# TLE986x register map
File version: 2.5
Registers are 32-bit, read-write, reset 0x0 unless marked. A register's access mark holds for its fields unless they carry their own. Offsets are from the block's base; [hi:lo] are bit positions.

## DMA
Base 0x50014000
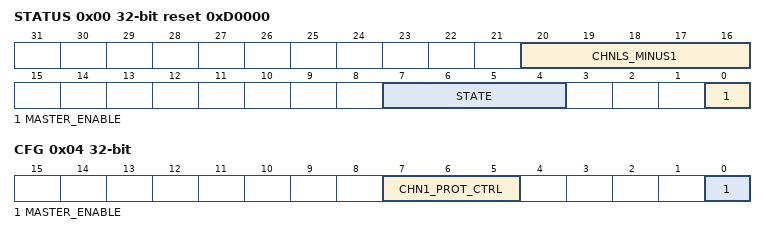
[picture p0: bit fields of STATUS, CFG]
0x00 STATUS ro reset 0xD0000 — DMA Status
  [20:16] CHNLS_MINUS1 — Available Channels minus 1
    13=controller configured to use 14 DMA channels
  [7:4] STATE — Current State of the Control State Machine
    0=idle; 1=reading channel controller date; 2=reading source data end pointer; 3=reading destination data end pointer; 4=reading source data; 5=writing destination data; 6=waiting for DMA request to clear; 7=writing channel controller data; 8=stalled; 9=done; 10=peripheral scatter-gather transition
  [0] MASTER_ENABLE — Enable Status of the Controller
    0=DISABLED (controller is disabled); 1=ENABLED (controller is enabled)
0x04 CFG wo — DMA Configuration
  [7:5] CHN1_PROT_CTRL
  [0] MASTER_ENABLE — Enable for the Controller
    0=DISABLE (disables the controller); 1=ENABLE (enables the controller)
0x08 CTRL_BASE_PTR — Channel Control Data Base Pointer
  [31:9] CTRL_BASE_PTR
0x0C ALT_CTRL_BASE_PTR ro reset 0x100 — Channel Alternate Control Data Base Pointer
  [31:0] ALT_CTRL_BASE_PTR — Base Address of the Alternate Data Structure
0x10 WAITONREQ_STATUS ro — Channel Wait on Request Status
  [13:0] WAITONREQ_STATUS
    0=LOW (dma_waitonreq[C] is LOW.); 1=HIGH (dma_waitonreq[C] is HIGH.)
0x14 CHNL_SW_REQUEST wo — Channel Software Request
  [13:0] CHNL_SW_REQUEST
    0=does not create a DMA request for channel C; 1=creates a DMA request for channel C
0x18 CHNL_USEBURST_SET — Channel Useburst Set
  [13:0] CHNL_USEBURST_SET — CHNL_USEBURST_SET: 0b0=on read: DMA channel n responds to requests that it receives on dma_req[C] or dma_sreq[C]. The controller performs 2, or single, bus transfers., 0b1=on read: DMA channel n does not respond to requests that it receives on dma_req[C] or dma_sreq[C]. The controller only reponds to dma_req[C] requests and performs 2 transfers., 0b0=on write: No effect. Use the CHNL_USEBURST_CLR Register to set bit [C] to 0., 0b1=on write: Disables dma_sreq[C] from generating DMA requests. The controller performs 2 transfers.,
0x1C CHNL_USEBURST_CLR wo — Channel Useburst Clear
  [13:0] CHNL_USEBURST_CLR
    0=No effect. Use the CHNL_USEBURST_SET Register to disable dma_sreq[] from generating requests.; 1=Enables dma_sreq[C] to generate DMA requests
0x20 CHNL_REQ_MASK_SET — Channel Request Mask Set
  [13:0] CHNL_REQ_MASK_SET — CHNL_REQ_MASK_SET: 0b0=on read: External requests are enabled for channel C., 0b1=on read: External requests are disabled for channel C., 0b0=on write: No effect. Use the CHNL_REQ_MASK_CLR Register to enable DMA requests., 0b1=on write: Disables dma_req[C] and dma_sreq[C] from generating DMA requests.,
0x24 CHNL_REQ_MASK_CLR wo — Channel Request Mask Clear
  [13:0] CHNL_REQ_MASK_CLR
    0=No effect. Use the CHNL_REQ_MASK_SET Register to disable dma_req[] and dma_sreq[] from generating requests.; 1=Enables dma_req[C] or dma_sreq[C] to generate DMA request
0x28 CHNL_ENABLE_SET — Channel Enable Set
  [13:0] CHNL_ENABLE_SET — CHNL_ENABLE_SET: 0b0=on read: Channel C is disabled., 0b1=on read: Channel C is enabled., 0b0=on write: No effect. Use the CHNL_ENABLE_CLR Register to disable a channel., 0b1=on write: Enables channel C.,
0x2C CHNL_ENABLE_CLR wo — Channel Enable Clear
  [13:0] CHNL_ENABLE_CLR
    0=No effect. Use the CHNL_ENABLE_SET Register to enable DMA channels.; 1=Disables channel C
0x30 CHNL_PRI_ALT_SET — Channel Primary-Alternate Set
  [13:0] CHNL_PRI_ALT_SET — CHNL_PRI_ALT_SET: 0b0=on read: DMA channel C is using the primary data structure., 0b1=on read: DMA channel C is using the alternate data structure., 0b0=on write: No effect. Use the CHNL_PRI_ALT_CLR Register to set bit [C] to 0., 0b1=on write: Selects the alternate data structure for channel C.,
0x34 CHNL_PRI_ALT_CLR wo — Channel Primary-Alternate Clear
  [13:0] CHNL_PRI_ALT_CLR
    0=No effect. Use the CHNL_PRI_ALT_SET Register to select the alternate data structure.; 1=Selects the primary data structure for channel C
0x38 CHNL_PRIORITY_SET — Channel Priority Set
  [13:0] CHNL_PRIORITY_SET — CHNL_PRIORITY_SET: 0b0=on read: DMA channel C is using the default priority level., 0b1=on read: DMA channel C is using a high priority level., 0b0=on write: No effect. Use the CHNL_ENABLE_CLR Register to set channel C to the default priority level., 0b1=on write: Channel C uses the high priority level.,
0x3C CHNL_PRIORITY_CLR wo — Channel Priority Clear
  [13:0] CHNL_PRIORITY_CLR
    0=No effect. Use the CHNL_ENABLE_SET Register to set channel C to the high priority level.; 1=Channel C uses the default priority level
0x4C ERR_CLR — Bus Error Clear
  [0] ERR_CLR — ERR_CLR: 0b0=on read: dma_err is LOW., 0b1=on read: dma_err is HIGH., 0b0=on write: No effect, status of dma_err is unchanged., 0b1=on write: Sets dma_err LOW.,
